# TC37XPD register map
Vendor: Infineon; Series: ATVMC; File version: 100
CPU: other r0p0, little endian, MPU, FPU, vendor SysTick, 4 interrupt priority bits
Registers are 32-bit, read-write, reset 0x0 unless marked. A register's access mark holds for its fields unless they carry their own. Offsets are from the block's base; [hi:lo] are bit positions; lines under a group give offsets from that group; {n}, {i} and the like mark numbered series.

## GETH (part 7 of 7)
Base 0xF001D000
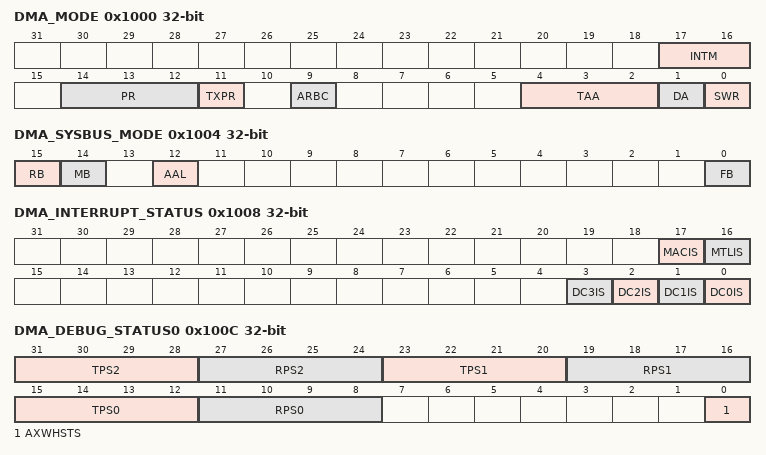
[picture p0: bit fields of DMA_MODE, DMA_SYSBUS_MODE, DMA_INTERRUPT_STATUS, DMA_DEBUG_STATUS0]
0x1000 DMA_MODE — DMA Bus Mode Register resetvalue={Application Reset:0x0}
  [17:16] INTM — Interrupt Mode INTM. This field defines the interrupt mode of DWC ether qos. The behavior of the following outputs changes depending on the following settings sbd perch tx intr o Transmit Per Channel Interrupt sbd perch rx intr o Receive Per Channel Interrupt sbd intr o Common Interrupt It also changes the behavior of the RI TI bits in the DMA CH0 Status. For more details please refer Table quot DWC ether qos Transfer Complete Interrupt Behavior quot . Value After Reset 0x0
  [14:12] PR — Priority Ratio PR. These bits control the priority ratio in weighted round robin arbitration between the Rx DMA and Tx DMA. These bits are valid only when the DA bit is reset. The priority ratio is Rx Tx or Tx Rx depending on whether the TXPR bit is reset or set. Value After Reset 0x0
  [11] TXPR — Transmit Priority TXPR. When set this bit indicates that the Tx DMA has higher priority than the Rx DMA during arbitration for the system side bus. Value After Reset 0x0
  [9] ARBC — Arbitration Control ARBC. When this bit is reset to 0 the DMA arbitrates as soon as the current burst transaction is completed. So in this mode the arbiter will miss the next subsequent request from the same DMA since there are inherent delays between the completion of 1 transfer request and the next transaction request generated from the same DMA. Consequently the WRR ratio becomes 1 1 irrespective of the programmed ratio. When this bit is set to 1 the DMA arbitration is delayed for a few clock cycles after the completion of current transaction so that the next request from the same DMA can be considered. This allows the arbiter to maintain WRR ratio as programmed.
  [4:2] TAA — Transmit Arbitration Algorithm TAA. This field is used to select the arbitration algorithm for the Transmit side when multiple Tx DMAs are selected. 011 111 Reserved Value After Reset 0x0
  [1] DA — DMA Tx or Rx Arbitration Scheme DA. This bit specifies the arbitration scheme between the Transmit and Receive paths of all channels The priority between the paths is according to the priority specified in Bits 14 12 and the priority weight is specified in the TXPR bit. The Tx path has priority over the Rx path when the TXPR bit is set. Otherwise the Rx path has priority over the Tx path. Value After Reset 0x0
  [0] SWR — Software Reset SWR. When this bit is set the MAC and the DMA controller reset the logic and all internal registers of the DMA MTL and MAC. This bit is automatically cleared after the reset operation is complete in all DWC ether qos clock domains. Before reprogramming any DWC ether qos register a value of zero should be read in this bit. This bit must be read at least 4 CSR clock cycles after it is written to 1. Note The reset operation is complete only when all resets in all active clock domains are de asserted. Therefore it is essential that all PHY inputs clocks applicable for the selected PHY interface are present for software reset completion. The time to complete the software reset operation depends on the frequency of the slowest active clock. Access restriction applies. Setting 1 sets. Self cleared. Setting 0 has no effect. Value After Reset 0x0
0x1004 DMA_SYSBUS_MODE — DMA System Bus Mode Register resetvalue={Application Reset:0x0}
  [15] RB — Rebuild INCRx Burst RB. When this bit is set high and the AHB master gets SPLIT RETRY or Early Burst Termination EBT response the AHB master interface rebuilds the pending beats of any initiated burst transfer with INCRx and SINGLE transfers. By default the AHB master interface rebuilds pending beats of an EBT with an unspecified INCR burst. Value After Reset 0x0
  [14] MB — Mixed Burst MB. When this bit is set high and the FB bit is low the AHB master performs undefined bursts transfers INCR for burst length of 16 or more. For burst length of 16 or less the AHB master performs fixed burst transfers INCRx and SINGLE . Value After Reset 0x0
  [12] AAL — Address Aligned Beats AAL. When this bit is set to 1 the EQOS AXI or EQOS AHB master performs address aligned burst transfers on Read and Write channels. Value After Reset 0x0
  [0] FB — Fixed Burst Length FB. When this bit is set to 1 the AHB master initiates burst transfers of specified length INCRx or SINGLE . When this bit is set to 0 the AHB master initiates transfers of unspecified length INCR or SINGLE transfers. Value After Reset 0x0
0x1008 DMA_INTERRUPT_STATUS ro — DMA Interrupt Status Register resetvalue={Application Reset:0x0}
  [17] MACIS — MAC Interrupt Status MACIS. This bit indicates an interrupt event in the MAC. To reset this bit to 1 b0 the software must read the corresponding register in the MAC to get the exact cause of the interrupt and clear its source. Value After Reset 0x0
  [16] MTLIS — MTL Interrupt Status MTLIS. This bit indicates an interrupt event in the MTL. To reset this bit to 1 b0 the software must read the corresponding register in the MTL to get the exact cause of the interrupt and clear its source. Value After Reset 0x0
  [n] DC{n}IS (n=0..3) — DMA Channel {n} Interrupt Status DC{n}IS. This bit indicates an interrupt event in DMA Channel {n}. To reset this bit to 1 b0 the software must read the corresponding register in DMA Channel {n} to get the exact cause of the interrupt and clear its source. Value After Reset 0x0
0x100C DMA_DEBUG_STATUS0 ro — DMA Debug Status 0 Register resetvalue={Application Reset:0x0}
  [31:28] TPS2 — DMA Channel 2 Transmit Process State TPS2. This field indicates the Tx DMA FSM state for Channel 2. This field is similar to the TPS0 field. Value After Reset 0x0
  [27:24] RPS2 — DMA Channel 2 Receive Process State RPS2. This field indicates the Rx DMA FSM state for Channel 2. This field is similar to the RPS0 field Value After Reset 0x0
  [23:20] TPS1 — DMA Channel 1 Transmit Process State TPS1. This field indicates the Tx DMA FSM state for Channel 1. This field is similar to the TPS0 field. Value After Reset 0x0
  [19:16] RPS1 — DMA Channel 1 Receive Process State RPS1. This field indicates the Rx DMA FSM state for Channel 1. This field is similar to the RPS0 field. Value After Reset 0x0
  [15:12] TPS0 — DMA Channel 0 Transmit Process State TPS0. This field indicates the Tx DMA FSM state for Channel 0 The MSB of this field always returns 0. This field does not generate an interrupt. Value After Reset 0x0
  [11:8] RPS0 — DMA Channel 0 Receive Process State RPS0. This field indicates the Rx DMA FSM state for Channel 0 The MSB of this field always returns 0. This field does not generate an interrupt. Value After Reset 0x0
  [0] AXWHSTS — AHB Master Status AXWHSTS. When high this bit indicates that the AHB master FSMs are in the non idle state. Value After Reset 0x0
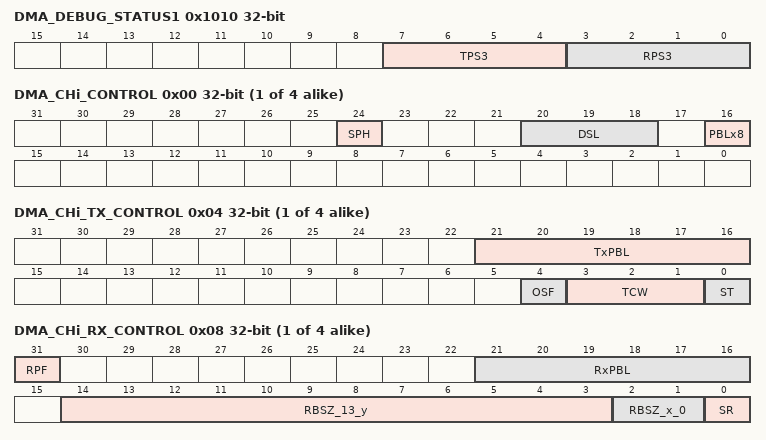
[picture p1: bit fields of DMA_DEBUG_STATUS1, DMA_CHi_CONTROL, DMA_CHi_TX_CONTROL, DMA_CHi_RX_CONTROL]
0x1010 DMA_DEBUG_STATUS1 ro — DMA Debug Status 1 Register resetvalue={Application Reset:0x0}
  [7:4] TPS3 — DMA Channel 3 Transmit Process State TPS3. This field indicates the Tx DMA FSM state for Channel 3. This field is similar to the TPS6 field. Value After Reset 0x0
  [3:0] RPS3 — DMA Channel 3 Receive Process State RPS3. This field indicates the Rx DMA FSM state for Channel 3. This field is similar to the RPS6 field. Value After Reset 0x0
{0x1100+0x80*i} DMA_CH[{i}] (i=0..3) group
  0x00 DMA_CHi_CONTROL — DMA Channel 0 Control Register resetvalue={Application Reset:0x0}
    [24] SPH — Split Headers SPH. When this bit is set the DMA splits the header and payload in the Receive path. The DMA writes the header to the Buffer Address1 of RDES0. The DMA writes the payload to the buffer to which the Buffer Address2 is pointing. The software must ensure that the header fits into the Receive buffers. If the header length exceeds the receive buffer size the DMA does not split the header and payload. This bit is available only if Enable Split Header Structure option is selected. Value After Reset 0x0
    [20:18] DSL — Descriptor Skip Length DSL. This bit specifies the Word Dword or Lword number depending on the 32 bit 64 bit or 128 bit bus to skip between two unchained descriptors. The address skipping starts from the end of the current descriptor to the start of the next descriptor. When the DSL value is equal to zero the DMA takes the descriptor table as contiguous. Value After Reset 0x0
    [16] PBLx8 — 8xPBL mode PBLx8. When this bit is set the PBL value programmed in Bits 21 16 in DMA CH0 Tx Control and Bits 21 16 in DMA CH0 Rx Control is multiplied by eight times. Therefore the DMA transfers the data in 8 16 32 64 128 and 256 beats depending on the PBL value. Value After Reset 0x0
  0x04 DMA_CHi_TX_CONTROL — DMA Channel 0 Transmit Control Register resetvalue={Application Reset:0x0}
    [21:16] TxPBL — Transmit Programmable Burst Length TxPBL. These bits indicate the maximum number of beats to be transferred in one DMA block data transfer. The DMA always attempts max burst as specified in PBL each time it starts a burst transfer on the application bus. You can program PBL with any of the following values 1 2 4 8 16 or 32. Any other value results in undefined behavior. To transfer more than 32 beats perform the following steps 1. Set the 8xPBL mode in DMA CH0 Control register. 2. Set the TxPBL. Note The maximum value of TxPBL must be less than or equal to half the Tx Queue size TQS field of MTL TxQ n Operation Mode register in terms of beats. This is required so that the Tx Queue has space to store at least another Tx PBL worth of data while the MTL Tx Queue Controller is transferring data to MAC. For example in 64 bit data width configurations the total locations in Tx Queue of size 512 bytes is 64 TxPBL and 8xPBL needs to be programmed to less than or equal to 32. Value After Reset 0x0
    [4] OSF — Operate on Second Packet OSF. When this bit is set it instructs the DMA to process the second packet of the Transmit data even before the status for the first packet is obtained. Value After Reset 0x0
    [3:1] TCW — Transmit Channel Weight TCW. This field indicates the weight assigned to the corresponding Transmit channel. When reset is complete this field is set to 0 for all channels by default resulting in equal weights to all channels. Value After Reset 0x0
    [0] ST — Start or Stop Transmission Command ST. When this bit is set transmission is placed in the Running state. The DMA checks the Transmit list at the current position for a packet to be transmitted. The DMA tries to acquire descriptor from either of the following positions The current position in the list This is the base address of the Transmit list set by the DMA CH0 TxDesc List Address register. The position at which the transmission was previously stopped If the DMA does not own the current descriptor the transmission enters the Suspended state and the TBU bit of the DMA CH0 Status register is set. The Start Transmission command is effective only when the transmission is stopped. If the command is issued before setting the DMA CH0 TxDesc List Address register the DMA behavior is unpredictable. When this bit is reset the transmission process is placed in the Stopped state after completing the transmission of the current packet. The Next Descriptor position in the Transmit list is saved and it becomes the current position when the transmission is restarted. To change the list address you need to program DMA CH0 TxDesc List Address register with a new value when this bit is reset. The new value is considered when this bit is set again. The stop transmission command is effective only when the transmission of the current packet is complete or the transmission is in the Suspended state. Value After Reset 0x0
  0x08 DMA_CHi_RX_CONTROL access per field — DMA Channel 0 Receive Control Register resetvalue={Application Reset:0x0}
    [31] RPF rw — DMA Rx Channel0 Packet Flush RPF. When this bit is set to 1 then DWC ether qos automatically flushes the packet from the Rx Queues destined to this DMA Rx Channel when it is stopped. When this bit remains set and the DMA is re started by the software driver the packets residing in the Rx Queues that were received when this RxDMA was stopped get flushed out. The packets that are received by the MAC after the RxDMA is re started are routed to the RxDMA. The flushing happens on the Read side of the Rx Queue. When this bit is set to 0 the DWC ether qos not flush the packet in the Rx Queue destined to this RxDMA Channel when it is STOP state. This may in turn cause head of line blocking in the corresponding RxQueue. Value After Reset 0x0
    [21:16] RxPBL rw — Receive Programmable Burst Length RxPBL. These bits indicate the maximum number of beats to be transferred in one DMA block data transfer. The DMA always attempts max burst as specified in PBL each time it starts a burst transfer on the application bus. You can program PBL with any of the following values 1 2 4 8 16 or 32. Any other value results in undefined behavior. To transfer more than 32 beats perform the following steps 1. Set the 8xPBL mode in the DMA CH0 Control register. 2. Set the RxPBL. Note The maximum value of RxPBL must be less than or equal to half the Rx Queue size RQS field of MTL RxQ n Operation Mode register in terms of beats. This is required so that the Rx Queue has space to store at least another Rx PBL worth of data while the Rx DMA is transferring a block of data. For example in 64 bit data width configurations the total locations in Rx Queue of size 512 bytes is 64 so RxPBL and 8xPBL needs to be programmed to less than or equal to 32. Value After Reset 0x0
    [14:3] RBSZ_13_y rw — Receive Buffer size High RBSZ 13 y. RBSZ 13 0 is split into two fields higher RBSZ 13 y and lower RBSZ x 0. The RBSZ 13 0 field indicates the size of the Rx buffers specified in bytes. The maximum buffer size is limited to 16K bytes. The buffer size is applicable to payload buffers when split headers are enabled. Note The buffer size must be a multiple of 4 8 or 16 depending on the data bus widths 32 bit 64 bit or 128 bit respectively . This is required even if the value of buffer address pointer is not aligned to data bus width. Hence the lower RBSZ x 0 bits are read only and the value is considered as allzero. Thus the RBSZ 13 y indicates the buffer size in terms of locations with the width same as bus width . Value After Reset 0x0
    [2:1] RBSZ_x_0 ro — Receive Buffer size Low RBSZ x 0. RBSZ 13 0 is split into two fields RBSZ 13 y and RBSZ x 0. The RBSZ x 0 is the lower field whose width is based on data bus width of the configuration. This field is of width 2 3 or 4 bits for 32 bit 64 bit or 128 bit data bus width respectively. This field is read only RO . Value After Reset 0x0
    [0] SR rw — Start or Stop Receive SR. When this bit is set the DMA tries to acquire the descriptor from the Receive list and processes the incoming packets. The DMA tries to acquire descriptor from either of the following positions The current position in the list This is the address set by the DMA CH0 RxDesc List Address register. The position at which the Rx process was previously stopped If the DMA does not own the current descriptor the reception is suspended and the RBU bit of the DMA CH0 Status register is set. The Start Receive command is effective only when the reception is stopped. If the command is issued before setting the DMA CH0 RxDesc List Address register the DMA behavior is unpredictable. When this bit is reset the Rx DMA operation is stopped after the transfer of the current packet. The next descriptor position in the Receive list is saved and it becomes the current position after the Rx process is restarted. The Stop Receive command is effective only when the Rx process is in the Running waiting for Rx packet or Suspended state. Value After Reset 0x0
  0x14 DMA_CHi_TXDESC_LIST_ADDRESS — DMA Channel 0 Transmit Descriptor List Address Register resetvalue={Application Reset:0x0}
    [31:2] TDESLA — Start of Transmit List TDESLA. This field contains the base address of the first descriptor in the Transmit descriptor list. The DMA ignores the LSB bits 1 0 2 0 or 3 0 for 32 bit 64 bit or 128 bit bus width and internally takes these bits as all zero. Therefore these LSB bits are read only RO . The width of this field depends on the configuration 31 2 for 32 bit configuration 31 3 for 64 bit configuration 31 4 for 128 bit configuration Value After Reset 0x0
  0x1C DMA_CHi_RXDESC_LIST_ADDRESS — DMA Channel 0 Receive Descriptor List Address Register resetvalue={Application Reset:0x0}
    [31:2] RDESLA — Start of Receive List RDESLA. This field contains the base address of the first descriptor in the Rx Descriptor list. The DMA ignores the LSB bits 1 0 2 0 or 3 0 for 32 bit 64 bit or 128 bit bus width and internally takes these bits as all zero. Therefore these LSB bits are read only RO . The width of this field depends on the configuration 31 2 for 32 bit configuration 31 3 for 64 bit configuration 31 4 for 128 bit configuration Value After Reset 0x0
  0x20 DMA_CHi_TXDESC_TAIL_POINTER — DMA Channel 0 Transmit Descriptor Tail Pointer Register resetvalue={Application Reset:0x0}
    [31:2] TDTP — Transmit Descriptor Tail Pointer TDTP. This field contains the tail pointer for the Tx descriptor ring. The software writes the tail pointer to add more descriptors to the Tx channel. The hardware tries to transmit all packets referenced by the descriptors between the head and the tail pointer registers. The width of this field depends on the configuration 31 2 for 32 bit configuration 31 3 for 64 bit configuration 31 4 for 128 bit configuration Value After Reset 0x0
  0x28 DMA_CHi_RXDESC_TAIL_POINTER — DMA Channel 0 Recieve Descriptor Tail Pointer Register resetvalue={Application Reset:0x0}
    [31:2] RDTP — Receive Descriptor Tail Pointer RDTP. This field contains the tail pointer for the Rx descriptor ring. The software writes the tail pointer to add more descriptors to the Rx channel. The hardware tries to write all received packets to the descriptors referenced between the head and the tail pointer registers. The width of this field depends on the configuration 31 2 for 32 bit configuration 31 3 for 64 bit configuration 31 4 for 128 bit configuration Value After Reset 0x0
  0x2C DMA_CHi_TXDESC_RING_LENGTH — DMA Channel 0 Transmit Descriptor Ring Length Register resetvalue={Application Reset:0x0}
    [9:0] TDRL — Transmit Descriptor Ring Length TDRL. This field sets the maximum number of Tx descriptors in the circular descriptor ring. The maximum number of descriptors is limited to 1K descriptors. Synopsys recommends a minimum ring descriptor length of 4. For example You can program any value up to 0x3FF in this field. This field is 10 bits wide if you program 0x3FF you can have 1024 descriptors. If you want to have 10 descriptors program it to a value of 0x9. Value After Reset 0x0
  0x30 DMA_CHi_RXDESC_RING_LENGTH — DMA Channel 0 Recieve Descriptor Ring Length Register resetvalue={Application Reset:0x0}
    [9:0] RDRL — Receive Descriptor Ring Length RDRL. This register sets the maximum number of Rx descriptors in the circular descriptor ring. The maximum number of descriptors is limited to 1K descriptors. For example You can program any value up to 0x3FF in this field. This field is 10 bits wide if you program 0x3FF you can have 1024 descriptors. If you want to have 10 descriptors program it to a value of 0x9. Value After Reset 0x0
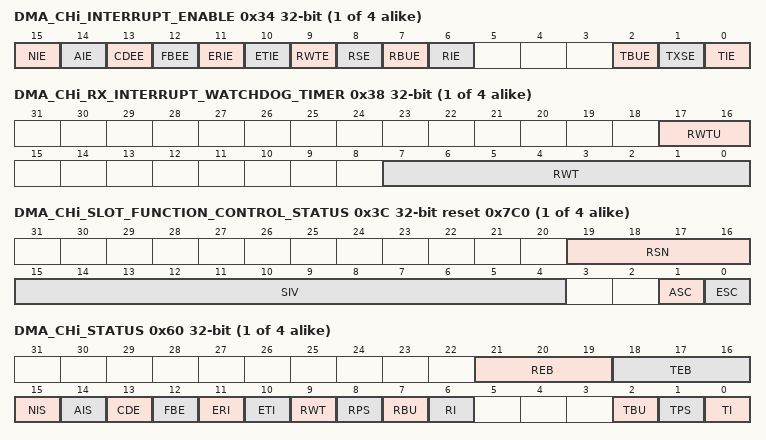
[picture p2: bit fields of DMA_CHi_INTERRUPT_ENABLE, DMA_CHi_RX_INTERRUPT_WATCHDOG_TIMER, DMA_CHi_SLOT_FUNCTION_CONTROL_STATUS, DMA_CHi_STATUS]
  0x34 DMA_CHi_INTERRUPT_ENABLE — DMA Channel 0 Interrupt Enable Register resetvalue={Application Reset:0x0}
    [15] NIE — Normal Interrupt Summary Enable NIE. When this bit is set the normal interrupt summary is enabled. This bit enables the following interrupts in the DMA CH0 Status register Bit 0 Transmit Interrupt Bit 2 Transmit Buffer Unavailable Bit 6 Receive Interrupt Bit 11 Early Receive Interrupt When this bit is reset the normal interrupt summary is disabled. Value After Reset 0x0
    [14] AIE — Abnormal Interrupt Summary Enable AIE. When this bit is set the abnormal interrupt summary is enabled. This bit enables the following interrupts in the DMA CH0 Status register Bit 1 Transmit Process Stopped Bit 7 Rx Buffer Unavailable Bit 8 Receive Process Stopped Bit 9 Receive Watchdog Timeout Bit 10 Early Transmit Interrupt Bit 12 Fatal Bus Error Bit 13 Context Descriptor Error When this bit is reset the abnormal interrupt summary is disabled. Value After Reset 0x0
    [13] CDEE — Context Descriptor Error Enable CDEE. When this bit is set along with the AIE bit the Context Descriptor error interrupt is enabled. When this bit is reset the Context Descriptor error interrupt is disabled. Value After Reset 0x0
    [12] FBEE — Fatal Bus Error Enable FBEE. When this bit is set along with the AIE bit the Fatal Bus error interrupt is enabled. When this bit is reset the Fatal Bus Error error interrupt is disabled. Value After Reset 0x0
    [11] ERIE — Early Receive Interrupt Enable ERIE. When this bit is set along with the NIE bit the Early Receive interrupt is enabled. When this bit is reset the Early Receive interrupt is disabled. Value After Reset 0x0
    [10] ETIE — Early Transmit Interrupt Enable ETIE. When this bit is set along with the AIE bit the Early Transmit interrupt is enabled. When this bit is reset the Early Transmit interrupt is disabled. Value After Reset 0x0
    [9] RWTE — Receive Watchdog Timeout Enable RWTE. When this bit is set along with the AIE bit the Receive Watchdog Timeout interrupt is enabled. When this bit is reset the Receive Watchdog Timeout interrupt is disabled. Value After Reset 0x0
    [8] RSE — Receive Stopped Enable RSE. When this bit is set along with the AIE bit the Receive Stopped Interrupt is enabled. When this bit is reset the Receive Stopped interrupt is disabled. Value After Reset 0x0
    [7] RBUE — Receive Buffer Unavailable Enable RBUE. When this bit is set along with the AIE bit the Receive Buffer Unavailable interrupt is enabled. When this bit is reset the Receive Buffer Unavailable interrupt is disabled. Value After Reset 0x0
    [6] RIE — Receive Interrupt Enable RIE. When this bit is set along with the NIE bit the Receive Interrupt is enabled. When this bit is reset the Receive Interrupt is disabled. Value After Reset 0x0
    [2] TBUE — Transmit Buffer Unavailable Enable TBUE. When this bit is set along with the NIE bit the Transmit Buffer Unavailable interrupt is enabled. When this bit is reset the Transmit Buffer Unavailable interrupt is disabled. Value After Reset 0x0
    [1] TXSE — Transmit Stopped Enable TXSE. When this bit is set along with the AIE bit the Transmission Stopped interrupt is enabled. When this bit is reset the Transmission Stopped interrupt is disabled. Value After Reset 0x0
    [0] TIE — Transmit Interrupt Enable TIE. When this bit is set along with the NIE bit the Transmit Interrupt is enabled. When this bit is reset the Transmit Interrupt is disabled. Value After Reset 0x0
  0x38 DMA_CHi_RX_INTERRUPT_WATCHDOG_TIMER — DMA Channel 0 Recieve Interrupt Watchdog Timer Register resetvalue={Application Reset:0x0}
    [17:16] RWTU — Receive Interrupt Watchdog Timer Count Units RWTU. This fields indicates the number of system clock cycles corresponding to one unit in RWT field. For example when RWT 2 and RWTU 1 the watchdog timer is set for 2 512 1024 system clock cycles. Value After Reset 0x0
    [7:0] RWT — Receive Interrupt Watchdog Timer Count RWT. This field indicates the number of system clock cycles multiplied by factor indicated in RWTU field for which the watchdog timer is set. The watchdog timer is triggered with the programmed value after the Rx DMA completes the transfer of a packet for which the RI bit is not set in the DMA CH0 Status register because of the setting of Interrupt Enable bit in the corresponding descriptor RDES3 30 . When the watchdog timer runs out the RI bit is set and the timer is stopped. The watchdog timer is reset when the RI bit is set high because of automatic setting of RI as per the Interrupt Enable bit RDES3 30 of any received packet. Value After Reset 0x0
  0x3C DMA_CHi_SLOT_FUNCTION_CONTROL_STATUS access per field reset 0x7C0 — DMA Channel 0 Slot Function Control and Status Register resetvalue={Application Reset:0x7C0}
    [19:16] RSN ro — Reference Slot Number RSN. This field gives the current value of the reference slot number in the DMA. It is used for slot comparison. Value After Reset 0x0
    [15:4] SIV rw — Slot Interval Value SIV. This field controls the period of the slot interval in which the TxDMA fetches the scheduled packets. A value of 0 specifies the slot interval of 1 us while the maximum value 4095 specifies the slot interval of 4096us. The default reset value is 0x07C which corresponds to slot interval of 125us. Value After Reset 0x7c
    [1] ASC rw — Advance Slot Check ASC. When set this bit enables the DMA to fetch the data from the buffer when the slot number SLOTNUM programmed in the Tx descriptor is equal to the reference slot number given in the RSN field or ahead of the reference slot number by up to two slots This bit is applicable only when the ESC bit is set. Value After Reset 0x0
    [0] ESC rw — Enable Slot Comparison ESC. When set this bit enables the checking of the slot numbers programmed in the Tx descriptor with the current reference given in the RSN field. The DMA fetches the data from the corresponding buffer only when the slot number is equal to the reference slot number or ahead of the reference slot number by one slot When reset this bit disables the checking of the slot numbers. The DMA fetches the data immediately after the descriptor is processed. Value After Reset 0x0
  0x44 DMA_CHi_CURRENT_APP_TXDESC ro — DMA Channel 0 Current Application Transmit Descriptor Register resetvalue={Application Reset:0x0}
    [31:0] CURTDESAPTR — Application Transmit Descriptor Address Pointer CURTDESAPTR. The DMA updates this pointer during Tx operation. This pointer is cleared on reset. Value After Reset 0x0
  0x4C DMA_CHi_CURRENT_APP_RXDESC ro — DMA Channel 0 Current Application Receive Descriptor Register resetvalue={Application Reset:0x0}
    [31:0] CURRDESAPTR — Application Receive Descriptor Address Pointer CURRDESAPTR. The DMA updates this pointer during Rx operation. This pointer is cleared on reset. Value After Reset 0x0
  0x54 DMA_CHi_CURRENT_APP_TXBUFFER ro — DMA Channel 0 Current Application Transmit Buffer Address Register resetvalue={Application Reset:0x0}
    [31:0] CURTBUFAPTR — Application Transmit Buffer Address Pointer CURTBUFAPTR. The DMA updates this pointer during Tx operation. This pointer is cleared on reset. Value After Reset 0x0
  0x5C DMA_CHi_CURRENT_APP_RXBUFFER ro — DMA Channel 0 Current Application Receive Buffer Address Register resetvalue={Application Reset:0x0}
    [31:0] CURRBUFAPTR — Application Receive Buffer Address Pointer CURRBUFAPTR. The DMA updates this pointer during Rx operation. This pointer is cleared on reset. Value After Reset 0x0
  0x60 DMA_CHi_STATUS access per field — DMA Channel 0 Status Register resetvalue={Application Reset:0x0}
    [21:19] REB ro — Rx DMA Error Bits REB. This field indicates the type of error that caused a Bus Error. For example error response on the AHB or AXI interface. Bit 21 1 B Error during data transfer by Rx DMA 0 B No Error during data transfer by Rx DMA Bit 20 1 B Error during descriptor access 0 B Error during data buffer access Bit 19 1 B Error during read transfer 0 B Error during write transfer This field is valid only when the FBE bit is set. This field does not generate an interrupt. Value After Reset 0x0
    [18:16] TEB ro — Tx DMA Error Bits TEB. This field indicates the type of error that caused a Bus Error. For example error response on the AHB or AXI interface. Bit 18 1 B Error during data transfer by Tx DMA 0 B No Error during data transfer by Tx DMA Bit 17 1 B Error during descriptor access 0 B Error during data buffer access Bit 16 1 B Error during read transfer 0 B Error during write transfer This field is valid only when the FBE bit is set. This field does not generate an interrupt. Value After Reset 0x0
    [15] NIS rw — Normal Interrupt Summary NIS. Normal Interrupt Summary bit value is the logical OR of the following bits when the corresponding interrupt bits are enabled in the DMA CH0 Interrupt Enable register Bit 0 Transmit Interrupt Bit 2 Transmit Buffer Unavailable Bit 6 Receive Interrupt Bit 11 Early Receive Interrupt Only unmasked bits interrupts for which interrupt enable is set in DMA CH0 Interrupt Enable register affect the Normal Interrupt Summary bit. This is a sticky bit. You must clear this bit by writing 1 to this bit each time a corresponding bit which causes NIS to be set is cleared. Access restriction applies. Self set to 1 on internal event. Setting 1 clears. Setting 0 has no effect. Value After Reset 0x0
    [14] AIS rw — Abnormal Interrupt Summary AIS. Abnormal Interrupt Summary bit value is the logical OR of the following when the corresponding interrupt bits are enabled in the DMA CH0 Interrupt Enable register Bit 1 Transmit Process Stopped Bit 7 Receive Buffer Unavailable Bit 8 Receive Process Stopped Bit 10 Early Transmit Interrupt Bit 12 Fatal Bus Error Bit 13 Context Descriptor Error Only unmasked bits affect the Abnormal Interrupt Summary bit. This is a sticky bit. You must clear this bit by writing 1 to this bit each time a corresponding bit which causes AIS to be set is cleared. Access restriction applies. Self set to 1 on internal event. Setting 1 clears. Setting 0 has no effect. Value After Reset 0x0
    [13] CDE rw — Context Descriptor Error CDE. This bit indicates that the DMA Tx Rx engine received a descriptor error which indicates invalid context in the middle of packet flow intermediate descriptor or all one s descriptor in Tx case and on Rx side it indicates DMA has read a descriptor with either of the buffer address as ones which is considered to be invalid.Access restriction applies. Self set to 1 on internal event. Setting 1 clears. Setting 0 has no effect. Value After Reset 0x0
    [12] FBE rw — Fatal Bus Error FBE. This bit indicates that a bus error occurred as described in the EB field . When this bit is set the corresponding DMA channel engine disables all bus accesses. Access restriction applies. Self set to 1 on internal event. Setting 1 clears. Setting 0 has no effect. Value After Reset 0x0
    [11] ERI rw — Early Receive Interrupt ERI. This bit indicates that the DMA filled the first data buffer of the packet. The RI bit of this register automatically clears this bit. Access restriction applies. Self set to 1 on internal event. Setting 1 clears. Setting 0 has no effect. Value After Reset 0x0
    [10] ETI rw — Early Transmit Interrupt ETI. This bit indicates that the packet to be transmitted is fully transferred to the MTL Tx FIFO. Access restriction applies. Self set to 1 on internal event. Setting 1 clears. Setting 0 has no effect. Value After Reset 0x0
    [9] RWT rw — Receive Watchdog Timeout RWT. This bit is asserted when a packet with length greater than 2 048 bytes 10 240 bytes when Jumbo Packet mode is enabled is received. Value After Reset 0x0
    [8] RPS rw — Receive Process Stopped RPS. This bit is asserted when the Rx process enters the Stopped state. Access restriction applies. Self set to 1 on internal event. Setting 1 clears. Setting 0 has no effect. Value After Reset 0x0
    [7] RBU rw — Receive Buffer Unavailable RBU. This bit indicates that the application owns the next descriptor in the Receive list and the DMA cannot acquire it. The Rx process is suspended. To resume processing Rx descriptors the application should change the ownership of the descriptor and issue a Receive Poll Demand command. If this command is not issued the Rx process resumes when the next recognized incoming packet is received. In ring mode the application should advance the Receive Descriptor Tail Pointer register of a channel. This bit is set only when the DMA owns the previous Rx descriptor. Access restriction applies. Self set to 1 on internal event. Setting 1 clears. Setting 0 has no effect. Value After Reset 0x0
    [6] RI rw — Receive Interrupt RI. This bit indicates that the packet reception is complete. When packet reception is complete Bit 31 of RDES3 is reset in the last descriptor and the specific packet status information is updated in the descriptor. The reception remains in the Running state. Access restriction applies. Self set to 1 on internal event. Setting 1 clears. Setting 0 has no effect. Value After Reset 0x0
    [2] TBU rw — Transmit Buffer Unavailable TBU. This bit indicates that the application owns the next descriptor in the Transmit list and the DMA cannot acquire it. Transmission is suspended. The TPS0 field of the DMA Debug Status0 register explains the Transmit Process state transitions. To resume processing the Transmit descriptors the application should do the following 1. Change the ownership of the descriptor by setting Bit 31 of TDES3. 2. Issue a Transmit Poll Demand command. For ring mode the application should advance the Transmit Descriptor Tail Pointer register of a channel. Access restriction applies. Self set to 1 on internal event. Setting 1 clears. Setting 0 has no effect. Value After Reset 0x0
    [1] TPS rw — Transmit Process Stopped TPS. This bit is set when the transmission is stopped. Access restriction applies. Self set to 1 on internal event. Setting 1 clears. Setting 0 has no effect. Value After Reset 0x0
    [0] TI rw — Transmit Interrupt TI. This bit indicates that the packet transmission is complete. When transmission is complete Bit 31 of TDES3 is reset in the last descriptor and the specific packet status information is updated in the descriptor. Access restriction applies. Self set to 1 on internal event. Setting 1 clears. Setting 0 has no effect. Value After Reset 0x0
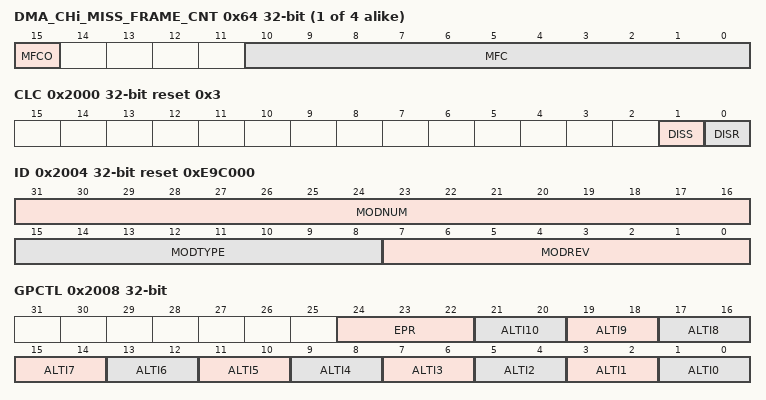
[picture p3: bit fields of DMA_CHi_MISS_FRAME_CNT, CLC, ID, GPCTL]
  0x64 DMA_CHi_MISS_FRAME_CNT ro — DMA Channel 0 Missed Frames Count Register resetvalue={Application Reset:0x0}
    [15] MFCO — Overflow status of the MFC Counter MFCO. When this bit is set then the MFC counter does not get incremented further. The bit gets cleared when this register is read. Access restriction applies. Clears on read. Self set to 1 on internal event. Value After Reset 0x0
    [10:0] MFC — Dropped Packet Counters MFC. This counter indicates the number of packet counters that are dropped by the DMA either because of bus error or because of programing RPF field in DMA CHx RX CONTROL register. The counter gets cleared when this register is read. Access restriction applies. Clears on read. Self set to 1 on internal event. Value After Reset 0x0
0x2000 CLC access per field reset 0x3 — Clock Control Register resetvalue={Application Reset:0x3}
  [1] DISS ro — Module Disable Status Bit DISS. Bit indicates the current status of the module.
  [0] DISR rw — Module Disable Request Bit DISR. Used for enable disable control of the module. The disable request is delayed internally until all pending transactions on the master SRI and slave SPB interface are completed.
0x2004 ID ro reset 0xE9C000 (reset mask 0xFFFFFF00) — Module Identification Register resetvalue={Application Reset:0x0E9C000}
  [31:16] MODNUM — Module Number Value MODNUM. This bit field defines the module identification number for the Mod Name 00E9 H
  [15:8] MODTYPE — Module Type MODTYPE. This bit field defines the module as a 32 bit module C0 H
  [7:0] MODREV — Module Revision Number MODREV. This bit field defines the module revision number. The value of a module revision starts with 01 H first revision . To be incremented eg. 2 for GMAC QoS
0x2008 GPCTL — General Purpose Control Register resetvalue={Application Reset:0x0}
  [24:22] EPR — External Phy Interface RMII Mode Bit EPR. Used to select the phy interface during module reset of MAC triggered by setting SWR bit of DMA Mode 160 Register. Note that the status of this bit is latched in during module reset only. Drives eth phy rmii o phy inff sel i 2 0 .
  [2n+1:2n] ALTI{n} (n=0..10) — Alternate Input Select ALTI10. Selects the alternate input for channel y. If no signal is connected to an alternate input it is connected to GND. If for one product no signal is connected to an alternate input it is connected to GND internally at module entity level. This allows to leave some signals unconnected in the application i.e. RXER CRS COL and save pins and external connection to GND. Map of signals demultiplexed by ALTI bit fields ALTI0 MDIO ALTI1 RXCLK REFCLK ALTI2 CRS ALTI3 COL ALTI4 RXDV CRSDV RCTL ALTI5 RXER ALTI6 RXD0 ALTI7 RXD1 ALTI8 RXD2 ALTI9 RXD3 ALTI10 TXCLK
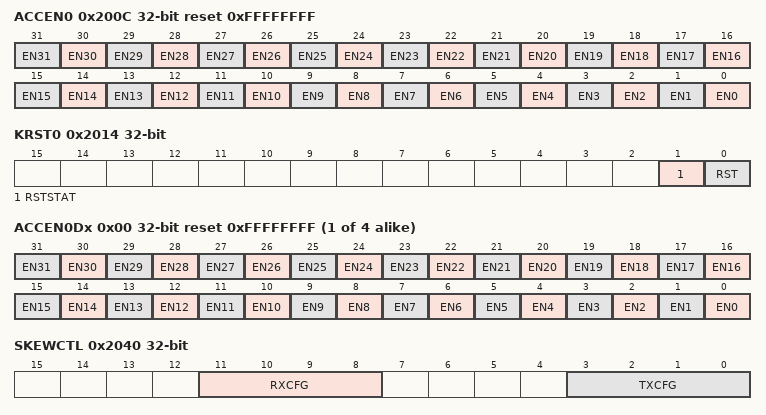
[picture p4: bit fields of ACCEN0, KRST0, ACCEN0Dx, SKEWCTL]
0x200C ACCEN0 reset 0xFFFFFFFF — Access Enable Register 0 resetvalue={Application Reset:0x0FFFFFFFF}
  [n] EN{n} (n=0..31) — Access Enable for Master TAG ID 31 EN31. This bit enables write access to the module kernel addresses for transactions with the Master TAG ID n
0x2014 KRST0 access per field — Kernel Reset Register 0 resetvalue={Application Reset:0x0}
  [1] RSTSTAT ro — Kernel Reset Status RSTSTAT. This bit indicates wether a kernel reset was executed or not. This bit is set by the BPI FPI after the execution of a kernel reset in the same clock cycle both reset bits. This bit can be cleared by writing with 180 1 180 to the CLR bit in the related KRSTCLR register.
  [0] RST rw — Kernel Reset RST. This reset bit can be used to request for a kernel reset. The kernel reset will be executed if the reset bits of both kernel registers are set and both master and slave interface are idle. The RST bit will be cleared re set to 180 0 180 by the BPI FPI after the kernel reset was executed.
0x2018 KRST1 — Kernel Reset Register 1 resetvalue={Application Reset:0x0}
  [0] RST — Kernel Reset RST. This reset bit can be used to request for a kernel reset. The kernel reset will be executed if the reset bits of both kernel reset registers is set and both master and slave interface are idle. The RST bit will be cleared re set to 180 0 180 by the BPI FPI after the kernel reset was executed.
0x201C KRSTCLR wo — Kernel Reset Status Clear Register resetvalue={Application Reset:0x0}
  [0] CLR — Kernel Reset Status Clear CLR. Read always as 0.
{0x2020+8i} ACCEND[{i}] (i=0..3) group
  0x00 ACCEN0Dx reset 0xFFFFFFFF — Access Enable Register 0 for DMA0 resetvalue={Application Reset:0x0FFFFFFFF}
    [n] EN{n} (n=0..31) — Access Enable for Master TAG ID 31 EN31. This bit enables write access to the module kernel addresses for transactions with the Master TAG ID n If the I O Test Mode of RGMII interface is active i.e. TEN bit in MAC TEST register is set to 8217 1 8217 write access to all ACCEN0Dx registers and from all master TAG IDs will be permanently enabled including those which are controlled by ACCENx registers . In this case the ACCEN0Dx register bits will be reused to define the RGMII TD RD loop test sequence as follows ACCEN0D0.bit 15 0 16 bit test sequence for TXD0 gt RXD0 ACCEN0D0.bit 31 16 16 bit test sequence for TXD1 gt RXD1 ACCEN0D1.bit 15 0 16 bit test sequence for TXD2 gt RXD2 ACCEN0D1.bit 31 16 16 bit test sequence for TXD3 gt RXD3 ACCEN0D2.bit 15 0 16 bit test sequence for TXCLK gt RXCLK ACCEN0D2.bit 31 16 16 bit test sequence for TCTL gt RCTL ACCEN0D3.bit 15 0 no function ACCEN0D3.bit 31 16 no function LSB value will be applied first MSB last in the 16 bit test data test sequence. The value of all ACCEND0x registers shall remain stable while a RGMII IF test operation is underway i.e. if MAC TEST.BUSY is set to 1 .
0x2040 SKEWCTL — Skew Control Register resetvalue={Application Reset:0x0}
  [11:8] RXCFG — RX Clock delay control for RGMII Mode RXCFG. Used to specify the receive timing skew in RGMII mode using integrated delay generation on RXCLK. In MII and RMII mode this is not active. Skew is RXCFG 222 22 ps. If cleared skew is 0 default skew generation switched off .
  [3:0] TXCFG — TX Clock delay control for RGMII Mode TXCFG. Used to specify the receive timing skew in RGMII mode using integrated delay generation on TXCLK. In MII and RMII mode this is not active. Skew is TXCFG 222 22 ps. If cleared skew is 0 default skew generation switched off .
